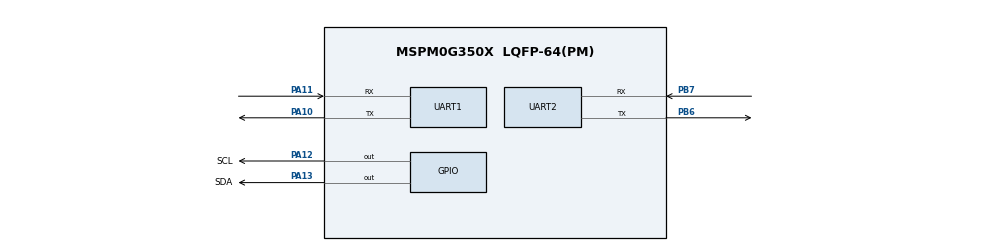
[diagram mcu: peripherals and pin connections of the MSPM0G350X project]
/**
 * @cliArgs --device "MSPM0G350X" --part "Default" --package "LQFP-64(PM)" --product "mspm0_sdk@2.02.00.05"
 * @versions {"tool":"1.21.1+3772"}
 */

/**
 * Import the modules used in this configuration.
 */
const SYSCTL  = scripting.addModule("/ti/driverlib/SYSCTL");
const SYSTICK = scripting.addModule("/ti/driverlib/SYSTICK");
const TIMER   = scripting.addModule("/ti/driverlib/TIMER", {}, false);
const TIMER1  = TIMER.addInstance();
const TIMER2  = TIMER.addInstance();
const GPIO    = scripting.addModule("/ti/driverlib/GPIO", {}, false);
const GPIO1   = GPIO.addInstance();
const UART    = scripting.addModule("/ti/driverlib/UART", {}, false);
const UART1   = UART.addInstance();
const UART2   = UART.addInstance();

/**
 * Write custom configuration values to the imported modules.
 */
const gate7  = system.clockTree["MFCLKGATE"];
gate7.enable = true;

SYSCTL.forceDefaultClkConfig = true;
SYSCTL.clockTreeEn           = true;

const Board = scripting.addModule("/ti/driverlib/Board", {}, false);

SYSTICK.periodEnable  = true;
SYSTICK.systickEnable = true;
SYSTICK.period        = 32;

/* TIMER_0: 100ms periodic — main loop timing */
TIMER1.$name            = "TIMER_0";
TIMER1.timerClkDiv      = 8;
TIMER1.timerClkPrescale = 40;
TIMER1.timerMode        = "PERIODIC";
TIMER1.timerPeriod      = "100 ms";
TIMER1.timerStartTimer  = true;
TIMER1.interrupts       = ["ZERO"];

/* TIMER_1: ~2ms one-shot — Modbus RTU inter-frame gap detection */
TIMER2.$name            = "TIMER_1";
TIMER2.timerClkDiv      = 8;
TIMER2.timerClkPrescale = 40;
TIMER2.timerMode        = "ONE_SHOT";
TIMER2.timerPeriod      = "2 ms";
TIMER2.timerStartTimer  = false;
TIMER2.interrupts       = ["ZERO"];

/* GPIO: Software I2C for IMU */
GPIO1.$name                          = "I2C";
GPIO1.port                           = "PORTA";
GPIO1.associatedPins.create(2);
GPIO1.associatedPins[0].$name        = "SDA";
GPIO1.associatedPins[0].initialValue = "SET";
GPIO1.associatedPins[1].$name        = "SCL";
GPIO1.associatedPins[1].initialValue = "SET";

/* UART0: Modbus RTU (RPi) — PA10 TX, PA11 RX */
UART1.$name                    = "UART_0";
UART1.uartClkSrc               = "MFCLK";
UART1.enabledInterrupts        = ["RX"];
UART1.targetBaudRate           = 115200;
UART1.peripheral.rxPin.$assign = "PA11";
UART1.peripheral.txPin.$assign = "PA10";
UART1.txPinConfig.$name        = "ti_driverlib_gpio_GPIOPinGeneric0";
UART1.rxPinConfig.$name        = "ti_driverlib_gpio_GPIOPinGeneric1";

/* UART1: Motor driver — PB6 TX, PB7 RX */
UART2.$name                    = "UART_1";
UART2.targetBaudRate           = 115200;
UART2.uartClkSrc               = "MFCLK";
UART2.enabledInterrupts        = ["RX"];
UART2.peripheral.$assign       = "UART1";
UART2.peripheral.rxPin.$assign = "PB7";
UART2.peripheral.txPin.$assign = "PB6";
UART2.txPinConfig.$name        = "ti_driverlib_gpio_GPIOPinGeneric2";
UART2.rxPinConfig.$name        = "ti_driverlib_gpio_GPIOPinGeneric3";

/**
 * Pinmux solution for unlocked pins/peripherals. This ensures that minor changes to the automatic solver in a future
 * version of the tool will not impact the pinmux you originally saw.  These lines can be completely deleted in order to
 * re-solve from scratch.
 */
Board.peripheral.$suggestSolution          = "DEBUGSS";
Board.peripheral.swclkPin.$suggestSolution = "PA20";
Board.peripheral.swdioPin.$suggestSolution = "PA19";
TIMER1.peripheral.$suggestSolution         = "TIMA0";
TIMER2.peripheral.$suggestSolution         = "TIMG0";
GPIO1.associatedPins[0].pin.$assign = "PA13";
GPIO1.associatedPins[1].pin.$assign = "PA12";
UART1.peripheral.$suggestSolution          = "UART0";
